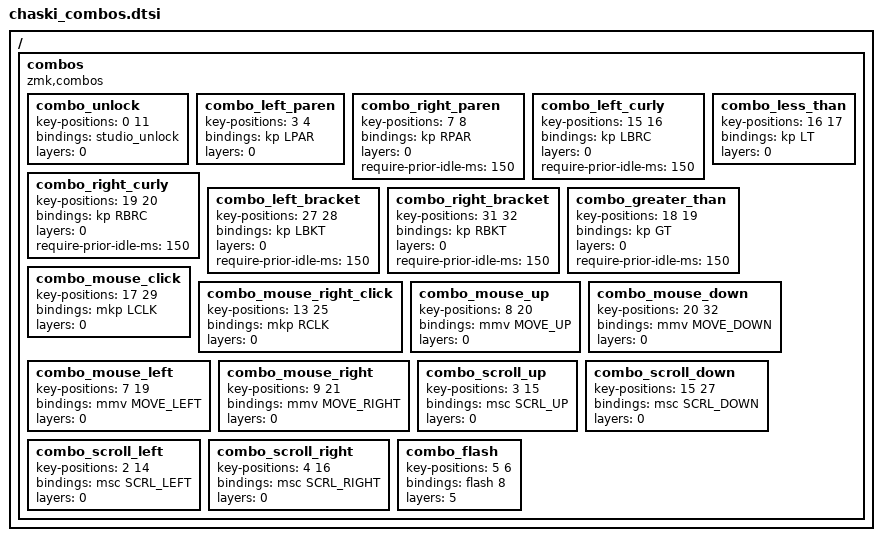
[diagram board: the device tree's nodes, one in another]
// Key positions for combos
// ┏━━━━┳━━━━┳━━━━┳━━━━┳━━━━┳━━━━┓                    ┏━━━━┳━━━━┳━━━━┳━━━━┳━━━━┳━━━━┓
// ┃ 0  ┃ 1  ┃ 2  ┃ 3  ┃ 4  ┃ 4  ┃                    ┃ 6  ┃ 7  ┃ 8  ┃ 9  ┃ 10 ┃ 11 ┃
// ┣━━━━╋━━━━╋━━━━╋━━━━╋━━━━╋━━━━┫                    ┣━━━━╋━━━━╋━━━━╋━━━━╋━━━━╋━━━━┫
// ┃ 12 ┃ 13 ┃ 14 ┃ 15 ┃<16>┃ 17 ┃                    ┃ 18 ┃<19>┃ 20 ┃ 21 ┃ 22 ┃ 23 ┃
// ┣━━━━╋━━━━╋━━━━╋━━━━╋━━━━╋━━━━┫                    ┣━━━━╋━━━━╋━━━━╋━━━━╋━━━━╋━━━━┫
// ┃ 24 ┃ 25 ┃ 26 ┃ 27 ┃ 28 ┃ 29 ┃                    ┃ 30 ┃ 31 ┃ 32 ┃ 33 ┃ 34 ┃ 35 ┃
// ┗━━━━┻━━━━┻━━━━┻━━━━┻━━━━╋━━━━╋━━━━┳━━━━┓┏━━━━┳━━━━╋━━━━╋━━━━┻━━━━┻━━━━┻━━━━┻━━━━┛
//                          ┃ 36 ┃<37>┃ 38 ┃┃ 39 ┃<40>┃ 41 ┃
//                          ┗━━━━┻━━━━┻━━━━┛┗━━━━┻━━━━┻━━━━┛

/ {
    combos {
        compatible = "zmk,combos";

        combo_unlock {
            key-positions = <0 11>;
            bindings = <&studio_unlock>;
            layers = <0>;
        };

        combo_left_paren {
            key-positions = <3 4>;
            bindings = <&kp LPAR>;
            layers = <0>;
        };

        combo_right_paren {
            key-positions = <7 8>;
            bindings = <&kp RPAR>;
            layers = <0>;
            require-prior-idle-ms = <150>;
        };

        combo_left_curly {
            key-positions = <15 16>;
            bindings = <&kp LBRC>;
            layers = <0>;
            require-prior-idle-ms = <150>;
        };

        combo_right_curly {
            key-positions = <19 20>;
            bindings = <&kp RBRC>;
            layers = <0>;
            require-prior-idle-ms = <150>;
        };

        combo_left_bracket {
            key-positions = <27 28>;
            bindings = <&kp LBKT>;
            layers = <0>;
            require-prior-idle-ms = <150>;
        };

        combo_right_bracket {
            key-positions = <31 32>;
            bindings = <&kp RBKT>;
            layers = <0>;
            require-prior-idle-ms = <150>;
        };

        combo_less_than {
            key-positions = <16 17>;
            bindings = <&kp LT>;
            layers = <0>;
        };

        combo_greater_than {
            key-positions = <18 19>;
            bindings = <&kp GT>;
            layers = <0>;
            require-prior-idle-ms = <150>;
        };

        combo_mouse_click {
            key-positions = <17 29>;
            bindings = <&mkp LCLK>;
            layers = <0>;
        };

        combo_mouse_right_click {
            key-positions = <13 25>;
            bindings = <&mkp RCLK>;
            layers = <0>;
        };

        combo_mouse_up {
            key-positions = <8 20>;
            bindings = <&mmv MOVE_UP>;
            layers = <0>;
        };

        combo_mouse_down {
            key-positions = <20 32>;
            bindings = <&mmv MOVE_DOWN>;
            layers = <0>;
        };

        combo_mouse_left {
            key-positions = <7 19>;
            bindings = <&mmv MOVE_LEFT>;
            layers = <0>;
        };

        combo_mouse_right {
            key-positions = <9 21>;
            bindings = <&mmv MOVE_RIGHT>;
            layers = <0>;
        };

        combo_scroll_up {
            key-positions = <3 15>;
            bindings = <&msc SCRL_UP>;
            layers = <0>;
        };

        combo_scroll_down {
            key-positions = <15 27>;
            bindings = <&msc SCRL_DOWN>;
            layers = <0>;
        };

        combo_scroll_left {
            key-positions = <2 14>;
            bindings = <&msc SCRL_LEFT>;
            layers = <0>;
        };

        combo_scroll_right {
            key-positions = <4 16>;
            bindings = <&msc SCRL_RIGHT>;
            layers = <0>;
        };

        // Combos are always executed on the central, so if we have a dongle
        // without an easily accessible reset button, we can use a combo to
        // put the central into bootloder mode
        combo_flash {
            key-positions = <5 6>;
            bindings = <&flash 8>;  // The layer number of the flash layer
            layers = <5>;  // The layer number of the layer where this combo is active
        };
    };
};

// vim: expandtab softtabstop=4 shiftwidth=4
